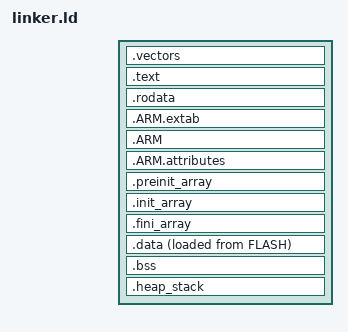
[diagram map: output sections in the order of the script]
/* memory map */
MEMORY
{
  FLASH (rx)      : ORIGIN = {{ROM_START}}, LENGTH = {{ROM_SIZE}}
  RAM (xrw)       : ORIGIN = {{RAM_START}}, LENGTH = {{RAM_SIZE}}
{{TCMRAM_MEMORY}}
}

ENTRY(Reset_Handler)

__stack_size = DEFINED(__stack_size) ? __stack_size : 2K;
__heap_size = DEFINED(__heap_size) ? __heap_size : 1K;

SECTIONS
{
  /* ISR vectors */
  .vectors :
  {
    . = ALIGN(4);
    KEEP(*(.vectors))
    . = ALIGN(4);
    __Vectors_End = .;
    __Vectors_Size = __Vectors_End - __gVectors;
  } >FLASH

  /* text section, such as program code */
  .text :
  {
    . = ALIGN(4);
    *(.text)
    *(.text*)
    *(.glue_7)
    *(.glue_7t)
    *(.eh_frame)
    KEEP (*(.init))
    KEEP (*(.fini))
    . = ALIGN(4);
    _etext = .;
  } >FLASH

  /* ro-data section, such as constant data */
  .rodata :
  {
    . = ALIGN(4);
    *(.rodata)
    *(.rodata*)
    . = ALIGN(4);
  } >FLASH

  /* exception process table */
  .ARM.extab :
  {
    *(.ARM.extab* .gnu.linkonce.armextab.*)
  } >FLASH

  /* exception process table index */
  .ARM :
  {
    __exidx_start = .;
    *(.ARM.exidx*)
    __exidx_end = .;
  } >FLASH

  /* ARM attributes */
  .ARM.attributes :
  {
   *(.ARM.attributes)
  } >FLASH

  .preinit_array :
  {
    PROVIDE_HIDDEN (__preinit_array_start = .);
    KEEP (*(.preinit_array*))
    PROVIDE_HIDDEN (__preinit_array_end = .);
  } >FLASH

  .init_array :
  {
    PROVIDE_HIDDEN (__init_array_start = .);
    KEEP (*(SORT(.init_array.*)))
    KEEP (*(.init_array*))
    PROVIDE_HIDDEN (__init_array_end = .);
  } >FLASH

  .fini_array :
  {
    PROVIDE_HIDDEN (__fini_array_start = .);
    KEEP (*(.fini_array*))
    KEEP (*(SORT(.fini_array.*)))
    PROVIDE_HIDDEN (__fini_array_end = .);
  } >FLASH

  /* provide some necessary symbols for initialized data */
  _sidata = LOADADDR(.data);
  .data :
  {
    . = ALIGN(4);
    _sdata = .;
    *(.data)
    *(.data*)
    . = ALIGN(4);
    _edata = .;
  } > RAM AT> FLASH

  /* provide some necessary symbols for uninitialized data */
  . = ALIGN(4);
  .bss :
  {
    . = ALIGN(4);
    _sbss = .;
    __bss_start__ = _sbss;
    *(.bss)
    *(.bss*)
    *(COMMON)
    . = ALIGN(4);
    _ebss = .;
    __bss_end__ = _ebss;
  } > RAM

  /* heap and stack space */
  .heap_stack :
  {
    . = ALIGN(8);
    PROVIDE ( end = _ebss );
    PROVIDE ( _end = _ebss );
    . = . + __heap_size;
    PROVIDE( _heap_end = . );
    . = . + __stack_size;
    PROVIDE( _sp = . );
    . = ALIGN(8);
  } > RAM

{{TCMRAM_SECTION}}
}

/* input sections */
GROUP(libgcc.a libc.a libm.a libnosys.a)
